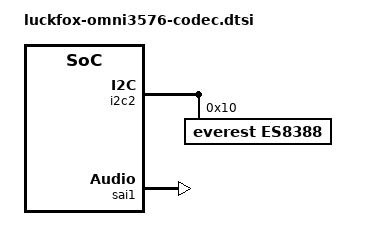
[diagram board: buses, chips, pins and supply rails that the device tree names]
// SPDX-License-Identifier: (GPL-2.0+ OR MIT)
/*
 * Copyright (c) 2024 Rockchip Electronics Co., Ltd.
 *
 */


/ {
    es8388_sound: es8388-sound {
		status = "okay";
		compatible = "rockchip,multicodecs-card";
		rockchip,card-name = "flipper-one-nau8822";
		rockchip,format = "i2s";
		rockchip,mclk-fs = <256>;
		rockchip,cpu = <&sai1>;
		rockchip,codec = <&es8388>;
		rockchip,audio-routing =
			"Headphone", "LOUT1",
			"Headphone", "ROUT1",
			"Speaker", "LOUT1",
			"Speaker", "ROUT1",
			"LINPUT2", "Main Mic",
			"RINPUT2", "Main Mic",
			"LINPUT2", "Headset Mic",
			"RINPUT2", "Headset Mic";
	};
};

&i2c2 {
	status = "okay";

	es8388: es8388@10 {
		status = "okay";
		#sound-dai-cells = <0>;
		compatible = "everest,es8388", "everest,es8323";
		reg = <0x10>;
		clocks = <&mclkout_sai1>;
		clock-names = "mclk";
		assigned-clocks = <&mclkout_sai1>;
		assigned-clock-rates = <12288000>;
		pinctrl-names = "default";
		pinctrl-0 = <&sai1m0_mclk>;
	};
};


&sai1 {
	status = "okay";
	pinctrl-names = "default";
	pinctrl-0 = <&sai1m0_lrck
		     &sai1m0_sclk
		     &sai1m0_sdi0
		     &sai1m0_sdo0>;
};
